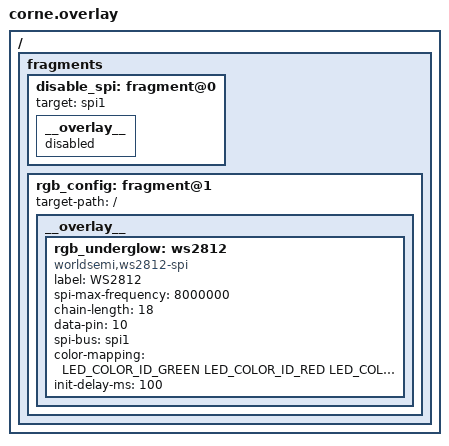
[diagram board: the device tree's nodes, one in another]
/dts-v1/;
/plugin/;

#include <dt-bindings/zmk/kscan.h>
#include <dt-bindings/led/led.h>

/ {
    fragments {
        // Fragment 0: Отключаем конфликтующие интерфейсы
        disable_spi: fragment@0 {
            target = <&spi1>;
            __overlay__ {
                status = "disabled";
            };
        };

        // Fragment 1: Настройка RGB подсветки
        rgb_config: fragment@1 {
            target-path = "/";
            __overlay__ {
                rgb_underglow: ws2812 {
                    compatible = "worldsemi,ws2812-spi";
                    label = "WS2812";
                    spi-max-frequency = <8000000>;
                    chain-length = <18>;    // 18 светодиодов на половину
                    data-pin = <10>;       // D10 (PA14) для nice!nano v2
                    spi-bus = <&spi1>;
                    // Дополнительные параметры:
                    color-mapping = <LED_COLOR_ID_GREEN 
                                   LED_COLOR_ID_RED 
                                   LED_COLOR_ID_BLUE>;
                    init-delay-ms = <100>;  // Задержка инициализации
                };
            };
        };

    };
};
